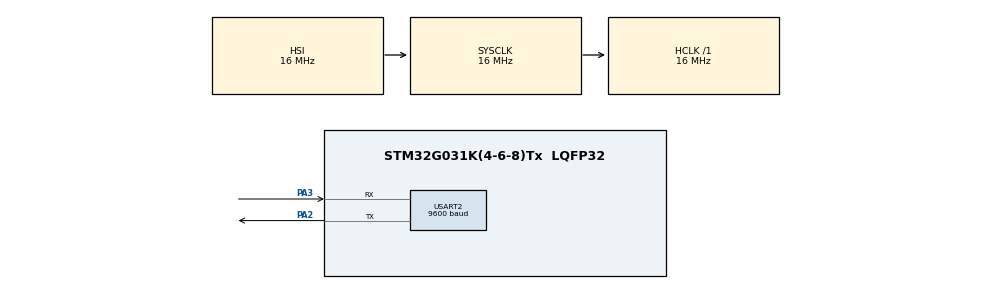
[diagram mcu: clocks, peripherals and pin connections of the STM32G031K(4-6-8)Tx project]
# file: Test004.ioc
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Mcu.Family=STM32G0
Mcu.Name=STM32G031K(4-6-8)Tx
Mcu.Package=LQFP32
PA13.Mode=Serial_Wire
PA13.Signal=SYS_SWDIO
PA14-BOOT0.Mode=Serial_Wire
PA14-BOOT0.Signal=SYS_SWCLK
PA2.Mode=Asynchronous
PA2.Signal=USART2_TX
PA3.Mode=Asynchronous
PA3.Signal=USART2_RX
ProjectManager.HeapSize=0x200
ProjectManager.StackSize=0x400
ProjectManager.TargetToolchain=STM32CubeIDE
RCC.AHBFreq_Value=16000000
RCC.CortexFreq_Value=16000000
RCC.EXTERNAL_CLOCK_VALUE=12288000
RCC.HCLKFreq_Value=16000000
RCC.HSE_VALUE=8000000
RCC.HSI_VALUE=16000000
RCC.LSE_VALUE=32768
RCC.SYSCLKFreq_VALUE=16000000
RCC.VCOOutputFreq_Value=128000000
USART2.BaudRate=9600
USART2.VirtualMode-Asynchronous=VM_ASYNC
board=custom

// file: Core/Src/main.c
/* USER CODE BEGIN Header */
/**
 *
 * Because printf redirecting to UART is not working without "\n" I prefer to have my own dbg_print() function
 * Tested on STM32G031K8T installed in Nucleo-G031K8 board
  ******************************************************************************
  * @file           : main.c
  * @brief          : Main program body
  ******************************************************************************
  * @attention
  *
  * <h2><center>&copy; Copyright (c) 2021 STMicroelectronics.
  * All rights reserved.</center></h2>
  *
  * This software component is licensed by ST under BSD 3-Clause license,
  * the "License"; You may not use this file except in compliance with the
  * License. You may obtain a copy of the License at:
  *                        opensource.org/licenses/BSD-3-Clause
  *
  ******************************************************************************
  */
/* USER CODE END Header */
#include "main.h"

/* USER CODE BEGIN Includes */

// dbg_tx() function implementation
#include <stdio.h>
#include <string.h>
/* USER CODE END Includes */

/* USER CODE BEGIN PD */

// dbg_tx() function implementation
#define     UART_DBG                    huart2
#define     HAL_UART_DBG_TIMEOUT_DUR    1000

/* USER CODE END PD */

UART_HandleTypeDef huart2;

/* USER CODE BEGIN PV */
// dbg_tx() example implementation
uint8_t uart_tx_buff[100] ;
const char* s = "float" ;
float f = 1.101 ;
/* USER CODE END PV */

void SystemClock_Config(void);
static void MX_GPIO_Init(void);
static void MX_USART2_UART_Init(void);
/* USER CODE BEGIN PFP */

// dbg_tx() function implementation
static HAL_StatusTypeDef dbg_tx ( uint8_t* buff , uint16_t len ) ;

/* USER CODE END PFP */

int main(void)
{

  /* MCU Configuration--------------------------------------------------------*/

  /* Reset of all peripherals, Initializes the Flash interface and the Systick. */
  HAL_Init();

  /* Configure the system clock */
  SystemClock_Config();

  /* Initialize all configured peripherals */
  MX_GPIO_Init();
  MX_USART2_UART_Init();
  /* USER CODE BEGIN 2 */

    // dbg_tx() example implementation
    //requires add "-u_printf_float" flag in: Other flag/Miscellaneous/MCU GCC Linker/Settings/C/C++ Build/Properties of the Test004 project
    sprintf ( (char *)uart_tx_buff , "Value of %s is: %f\r\n" , s , f ) ;
    dbg_tx ( uart_tx_buff , (uint16_t)strlen ( (const char*)uart_tx_buff ) ) ;

    uint16_t s_strlen = (uint16_t) strlen ( (const char*) uart_tx_buff ) ;
    uint16_t s_sizeof = (uint16_t) sizeof ( uart_tx_buff ) ;
    uint16_t s_sizeof2 = (uint16_t) ( sizeof ( uart_tx_buff ) / sizeof ( uart_tx_buff[0] ) ) ;

    sprintf ( (char *)uart_tx_buff , "Value of strlen is: %d\r\n" , s_strlen ) ;
    dbg_tx ( uart_tx_buff , (uint16_t)strlen ( (const char*)uart_tx_buff ) ) ;
    sprintf ( (char *)uart_tx_buff , "Value of sizeof is: %d\r\n" , s_sizeof ) ;
    dbg_tx ( uart_tx_buff , (uint16_t)strlen ( (const char*)uart_tx_buff ) ) ;
    sprintf ( (char *)uart_tx_buff , "Value of sizeof2 is: %d\r\n" , s_sizeof2 ) ;
    dbg_tx ( uart_tx_buff , (uint16_t)strlen ( (const char*)uart_tx_buff ) ) ;

    /* USER CODE END 2 */

  /* Infinite loop */
  while (1)
  {

  }
}

void SystemClock_Config(void)
{
  RCC_OscInitTypeDef RCC_OscInitStruct = {0};
  RCC_ClkInitTypeDef RCC_ClkInitStruct = {0};

  /** Configure the main internal regulator output voltage
  */
  HAL_PWREx_ControlVoltageScaling(PWR_REGULATOR_VOLTAGE_SCALE1);
  /** Initializes the RCC Oscillators according to the specified parameters
  * in the RCC_OscInitTypeDef structure.
  */
  RCC_OscInitStruct.OscillatorType = RCC_OSCILLATORTYPE_HSI;
  RCC_OscInitStruct.HSIState = RCC_HSI_ON;
  RCC_OscInitStruct.HSIDiv = RCC_HSI_DIV1;
  RCC_OscInitStruct.HSICalibrationValue = RCC_HSICALIBRATION_DEFAULT;
  RCC_OscInitStruct.PLL.PLLState = RCC_PLL_NONE;
  if (HAL_RCC_OscConfig(&RCC_OscInitStruct) != HAL_OK)
  {
    Error_Handler();
  }
  /** Initializes the CPU, AHB and APB buses clocks
  */
  RCC_ClkInitStruct.ClockType = RCC_CLOCKTYPE_HCLK|RCC_CLOCKTYPE_SYSCLK
                              |RCC_CLOCKTYPE_PCLK1;
  RCC_ClkInitStruct.SYSCLKSource = RCC_SYSCLKSOURCE_HSI;
  RCC_ClkInitStruct.AHBCLKDivider = RCC_SYSCLK_DIV1;
  RCC_ClkInitStruct.APB1CLKDivider = RCC_HCLK_DIV1;

  if (HAL_RCC_ClockConfig(&RCC_ClkInitStruct, FLASH_LATENCY_0) != HAL_OK)
  {
    Error_Handler();
  }
}

static void MX_USART2_UART_Init(void)
{

  huart2.Instance = USART2;
  huart2.Init.BaudRate = 9600;
  huart2.Init.WordLength = UART_WORDLENGTH_8B;
  huart2.Init.StopBits = UART_STOPBITS_1;
  huart2.Init.Parity = UART_PARITY_NONE;
  huart2.Init.Mode = UART_MODE_TX_RX;
  huart2.Init.HwFlowCtl = UART_HWCONTROL_NONE;
  huart2.Init.OverSampling = UART_OVERSAMPLING_16;
  huart2.Init.OneBitSampling = UART_ONE_BIT_SAMPLE_DISABLE;
  huart2.Init.ClockPrescaler = UART_PRESCALER_DIV1;
  huart2.AdvancedInit.AdvFeatureInit = UART_ADVFEATURE_NO_INIT;
  if (HAL_UART_Init(&huart2) != HAL_OK)
  {
    Error_Handler();
  }

}

static void MX_GPIO_Init(void)
{

  /* GPIO Ports Clock Enable */
  __HAL_RCC_GPIOA_CLK_ENABLE();

}

/* USER CODE BEGIN 4 */

// dbg_tx() function implementation
static HAL_StatusTypeDef dbg_tx ( uint8_t* buff , uint16_t len )
{
    return HAL_UART_Transmit ( &UART_DBG , buff , len , HAL_UART_DBG_TIMEOUT_DUR ) ;
}

/* USER CODE END 4 */

void Error_Handler(void)
{
  __disable_irq();
  while (1)
  {
  }
}

/************************ (C) COPYRIGHT STMicroelectronics *****END OF FILE****/
